# cslr_uartc5501_001 register map
Vendor: Texas Instruments
Peripheral module from a debugger description file.
Registers are 16-bit, access per field, reset 0x0 unless marked. A register's access mark holds for its fields unless they carry their own. Offsets are as the file gives them; lines under a group give offsets from that group; [hi:lo] are bit positions; {n}, {i} and the like mark numbered series; 'fields as' and 'values as' point back to an identical list; <NAME> marks a mode.

## UART — Universal Asynchronous Receiver/Transmitter
0x00 URRBR ro (reset mask 0xFF00) — Receiver Buffer Register
  [7:0] DATA — Received data.
0x00 URTHR — Transmitter Holding Register
  [7:5] DATA wo — Transmit data.
0x00 URDLL (reset mask 0xFF00) — Divisor Latch Registers
  [7:0] DLL rw — Use DLL to program the least significant bits of the baud rate divisor.
0x01 URDLM (reset mask 0xFF00) — Divisor Latch Registers
  [7:0] DLM rw — Use DLM to program the most significant bits of the baud rate divisor.
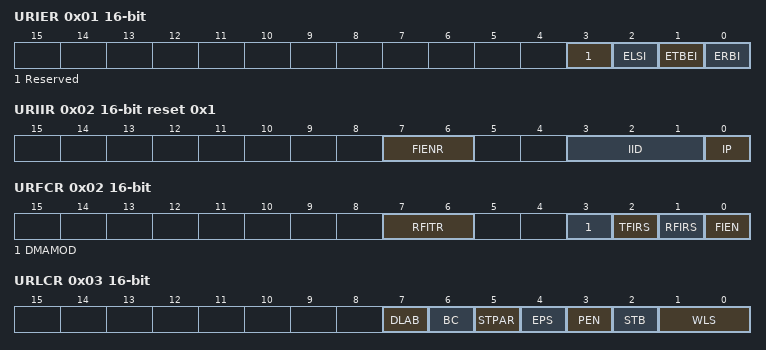
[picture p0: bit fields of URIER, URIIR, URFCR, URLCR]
0x01 URIER — Interrupt Enable Register
  [3] Reserved rw — Always write 0 to this bit.
  [2] ELSI rw — Enable bit for the receiver line status interrupt request
    0=Interrupt request disabled; 1=Interrupt request enabled
  [1] ETBEI rw — Enable bit for the THR-empty interrupt request
    0=Interrupt request disabled; 1=Interrupt request enabled
  [0] ERBI rw — Enable bit for the receiver data-ready interrupt request and the receiver time-out interrupt request
    0=Interrupt request disabled; 1=Interrupt request enabled
0x02 URIIR ro reset 0x1 — Interrupt Identification Register
  [7:6] FIENR — FIFO status bit
    0=The non-FIFO (TL16C450) mode is selected (FIEN = 0 in URFCR); 3=The FIFO mode is selected (FIEN = 1 in URFCR)
  [3:1] IID — Interrupt identification field.
    0=No interrupt; 1=Transmitter holding register empty interrupt (priority 3); 2=Receiver data-ready interrupt (priority 2); 3=Receiver line status interrupt (priority 1); 6=Receiver time-out interrupt (priority 2)
  [0] IP — Interrupt pending bit.
    0=An interrupt is pending; 1=No interrupt is pending
0x02 URFCR — FIFO Control Register
  [7:6] RFITR wo — Receiver FIFO trigger level bits.
    0=1 byte; 1=4 bytes; 2=8 bytes; 3=14 bytes
  [3] DMAMOD wo — DMA mode bit.
  [2] TFIRS wo — Transmitter FIFO reset bit
    0=The bit has been cleared; 1=This bit, when set, clears the transmitter FIFO pointer
  [1] RFIRS wo — Receive FIFO reset bit
    0=The bit has been cleared; 1=This bit, when set, clears the receiver FIFO pointer
  [0] FIEN wo — FIFO enable bit
    0=Non-FIFO mode; 1=FIFO mode
0x03 URLCR — Line Control Register
  [7] DLAB rw — Divisor latch access bit.
    0=URRBR, URTHR, and URIER selected; 1=URDLL and URDLM selected
  [6] BC rw — Break control bit.
    0=Break condition disabled; 1=Break condition enabled
  [5] STPAR rw — Stick parity bit.
    0=Stick parity disabled; 1=Stick parity enabled
  [4] EPS rw — Even parity select bit.
    0=Odd parity selected; 1=Even parity selected
  [3] PEN rw — Parity enable bit.
    0=Parity disabled; 1=Parity enabled
  [2] STB rw — Stop-bit mode bit.
    0=One stop bit is generated in the data; 1=The number of stop bits generated is dependent on the word length selected with bits 0 and 1 (WLS)
  [1:0] WLS rw — Word length select bits.
    {v}={v+5} bits (v=0..3)
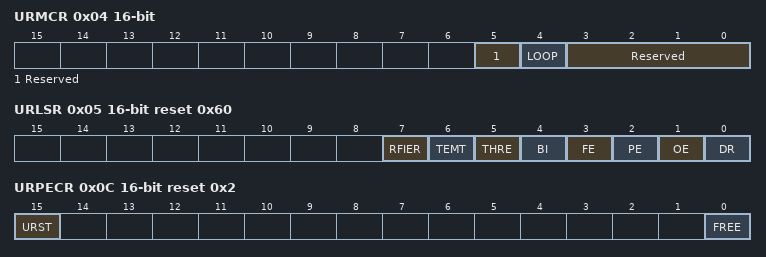
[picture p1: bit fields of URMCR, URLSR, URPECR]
0x04 URMCR — Modem Control Register
  [5] Reserved rw — Write 0 to this bit.
  [4] LOOP rw — Loopback enable bit.
    0=Loopback disabled; 1=Loopback enabled
  [3:0] Reserved rw — Write 0s to these bits.
0x05 URLSR ro reset 0x60 — Line Status Register
  [7] RFIER — Receiver FIFO error indicator
    0=There has been no error, or RFIER was cleared because the CPU read the erroneous character from the receiver buffer register (URRBR); 1=There is a parity error, framing error, or break indicator in URRBR
  [6] TEMT — Transmitter empty indicator
    0=Either the transmitter holding register (URTHR) or the transmitter shift register (URTSR) contains a character; 1=Both URTHR and URTSR are empty
  [5] THRE — Transmitter holding register empty indicator.
    0=URTHR is not empty; 1=URTHR is empty (ready to accept a new character)
  [4] BI — Break indicator.
    0=No break has been detected, or BI was cleared because the CPU read the erroneous character from the receiver buffer register (URRBR); 1=A break has been detected with the character in URRBR
  [3] FE — Framing error (FE) indicator.
    0=No framing error has been detected, or FE was cleared because the CPU read the erroneous data from the receiver buffer register (URRBR); 1=A framing error has been detected with the character in URRBR
  [2] PE — Parity error (PE) indicator.
    0=No parity error has been detected, or PE was cleared because the CPU read the erroneous data from the receiver buffer register (URRBR); 1=A parity error has been detected with the character in URRBR
  [1] OE — Overrun error (OE) indicator.
    0=No overrun error has been detected, or OE was cleared because the CPU read the content of the line status register (URLSR); 1=An overrun error has been detected
  [0] DR — Data-ready (DR) indicator for the receiver.
    0=Data is not ready, or DR was cleared because the character was read from the receiver buffer register (URRBR); 1=Data is ready
0x07 URSCR (reset mask 0xFF00) — Scratch Register
  [7:0] SCR rw — This field can be used as a temporary data storage location.
0x0C URPECR access not given reset 0x2 — Power and Emulation Control Register
  [15] URST rw — UART software reset bit
    0=The receiver and transmitter are disabled and in the reset state; 1=The receiver and transmitter are enabled
  [0] FREE rw — This emulation mode bit determines the functionality of the UART in the case of an emulator-related operation such as a debugger breakpoint.
    0=If a character transfer is not in progress, the UART stops immediately; 1=The UART does not stop in response to the emulator-related operation
